VERSION ""

NS_ :

BS_:

BU_: ECU_3 ECU_1 ECU_2
VAL_TABLE_ SignalValueTable1 4 "pending" 3 "undefined" 2 "error" 1 "active" 0 "inactive" ;

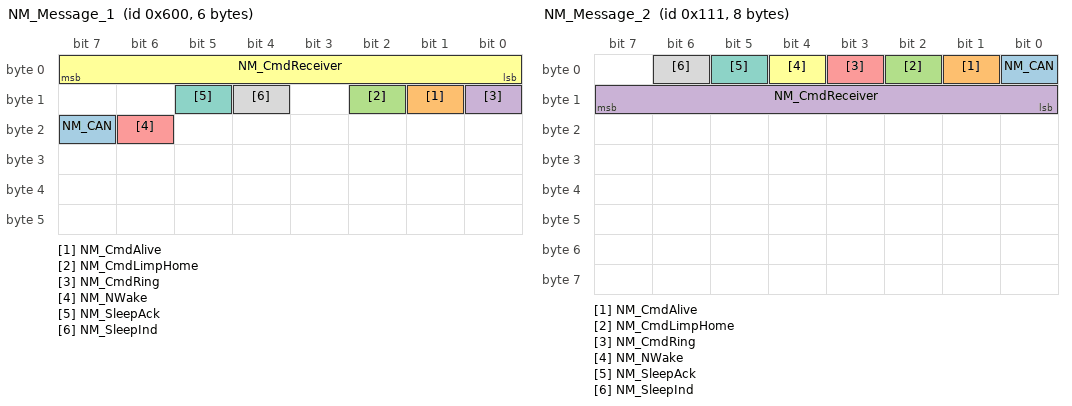
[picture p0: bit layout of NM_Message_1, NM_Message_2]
BO_ 1536 NM_Message_1: 6 ECU_1
 SG_ NM_CAN : 23|1@1+ (1,0) [0|1] "" Vector__XXX
 SG_ NM_CmdAlive : 9|1@1+ (1,0) [0|1] "" Vector__XXX
 SG_ NM_CmdLimpHome : 10|1@1+ (1,0) [0|1] "" Vector__XXX
 SG_ NM_CmdRing : 8|1@1+ (1,0) [0|1] "" Vector__XXX
 SG_ NM_NWake : 22|1@1+ (1,0) [0|1] "" Vector__XXX
 SG_ NM_CmdReceiver : 0|8@1+ (1,0) [0|255] "" Vector__XXX
 SG_ NM_SleepAck : 13|1@1+ (1,0) [0|1] "" Vector__XXX
 SG_ NM_SleepInd : 12|1@1+ (1,0) [0|1] "" Vector__XXX

BO_ 273 NM_Message_2: 8 ECU_2
 SG_ NM_CAN : 0|1@1+ (1,0) [0|1] "" Vector__XXX
 SG_ NM_CmdAlive : 1|1@1+ (1,0) [0|1] "" Vector__XXX
 SG_ NM_CmdLimpHome : 2|1@1+ (1,0) [0|1] "" Vector__XXX
 SG_ NM_CmdReceiver : 8|8@1+ (1,0) [0|255] "" Vector__XXX
 SG_ NM_CmdRing : 3|1@1+ (1,0) [0|1] "" Vector__XXX
 SG_ NM_NWake : 4|1@1+ (1,0) [0|1] "" Vector__XXX
 SG_ NM_SleepAck : 5|1@1+ (1,0) [0|1] "" Vector__XXX
 SG_ NM_SleepInd : 6|1@1+ (1,0) [0|1] "" Vector__XXX

BA_DEF_  "BusType" STRING ;
BA_DEF_DEF_  "BusType" "";
BA_ "BusType" "CAN";
